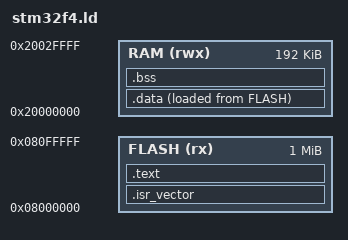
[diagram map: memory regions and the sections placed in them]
MEMORY
{
  FLASH (rx)  : ORIGIN = 0x08000000, LENGTH = 1024K
  RAM   (rwx) : ORIGIN = 0x20000000, LENGTH = 192K
}

__stack_top = 0x20000000 + 192K;

ENTRY(Reset_Handler)

SECTIONS
{
  .isr_vector :
  {
    . = ALIGN(4);
    KEEP(*(.isr_vector))
    . = ALIGN(4);
  } > FLASH

  .text :
  {
    *(.text*)
    *(.rodata*)
    *(.glue_7*)
    *(.glue_7t*)
    . = ALIGN(4);
  } > FLASH

  _sidata = LOADADDR(.data);

  .data :
  {
    . = ALIGN(4);
    _sdata = .;
    *(.data*)
    . = ALIGN(4);
    _edata = .;
  } > RAM AT > FLASH

  .bss :
  {
    . = ALIGN(4);
    _sbss = .;
    *(.bss*)
    *(COMMON)
    . = ALIGN(4);
    _ebss = .;
  } > RAM

  . = ALIGN(8);
  _end = .;
}
